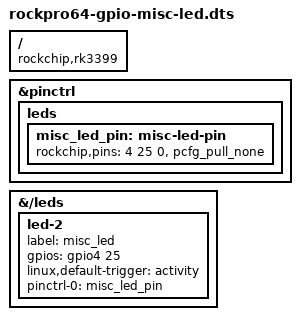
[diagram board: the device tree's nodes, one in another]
/*  For Pine RockPro64 boards only!! */

/dts-v1/;
/plugin/;

/ {
    compatible = "rockchip,rk3399";

    fragment@0 {
        target = <&pinctrl>;
        __overlay__ {
            leds {
                misc_led_pin: misc-led-pin {
                    /* gpio4 25 (D1) , Function 0 (GPIO), no pull */
                    rockchip,pins = <4 25 0 &pcfg_pull_none>;
                };
            };
        };
    };

    fragment@1 {
        /* target-path is okay if /leds exists, otherwise use target = <&leds> */
        target-path = "/leds"; 
        __overlay__ {
            led-2 {
                label = "misc_led";
                gpios = <&gpio4 25 0>; /* 0 is GPIO_ACTIVE_HIGH */
                linux,default-trigger = "activity";
                pinctrl-names = "default";
                pinctrl-0 = <&misc_led_pin>;
            };
        };
    };
};

/* fixups: 
     pcfg_pull_none == 0xcb (phandle for /pinctrl/pcfg-pull-none, bias == none )
     gpio4 == 0x93 (phandle for /pinctrl/gpio@ff790000) 
*/

/* 

Defines from the 'gpios = <&gpio[#] [pin] [state]>'  line
  pin:  linux/include/dt-bindings/pinctrl/rockchip.h:   #define GPIO4_D1(22)	   25 (153)
state:  linux/include/linux/gpio/machine.h:             #define GPIO_ACTIVE_HIGH   (0 << 0)

        (other available GPIOs, that aren't overloaded:  GPIO1_A4 (16), GPIO4_C5(18), GPIO1_B5(26) )

        ## To install:

        * dtc -@ -I dts -O dtb -o /boot/dtb/rockchip/overlay/rockchip-gpio-misc-led.dtbo rockpro64-gpio-misc-led.dts

        *  Edit /boot/orangepiEnv.txt and add
                overlays=gpio-misc-led   ( or:  orverlays=[existing] gpio-misc-led )

        *  reboot

*/
